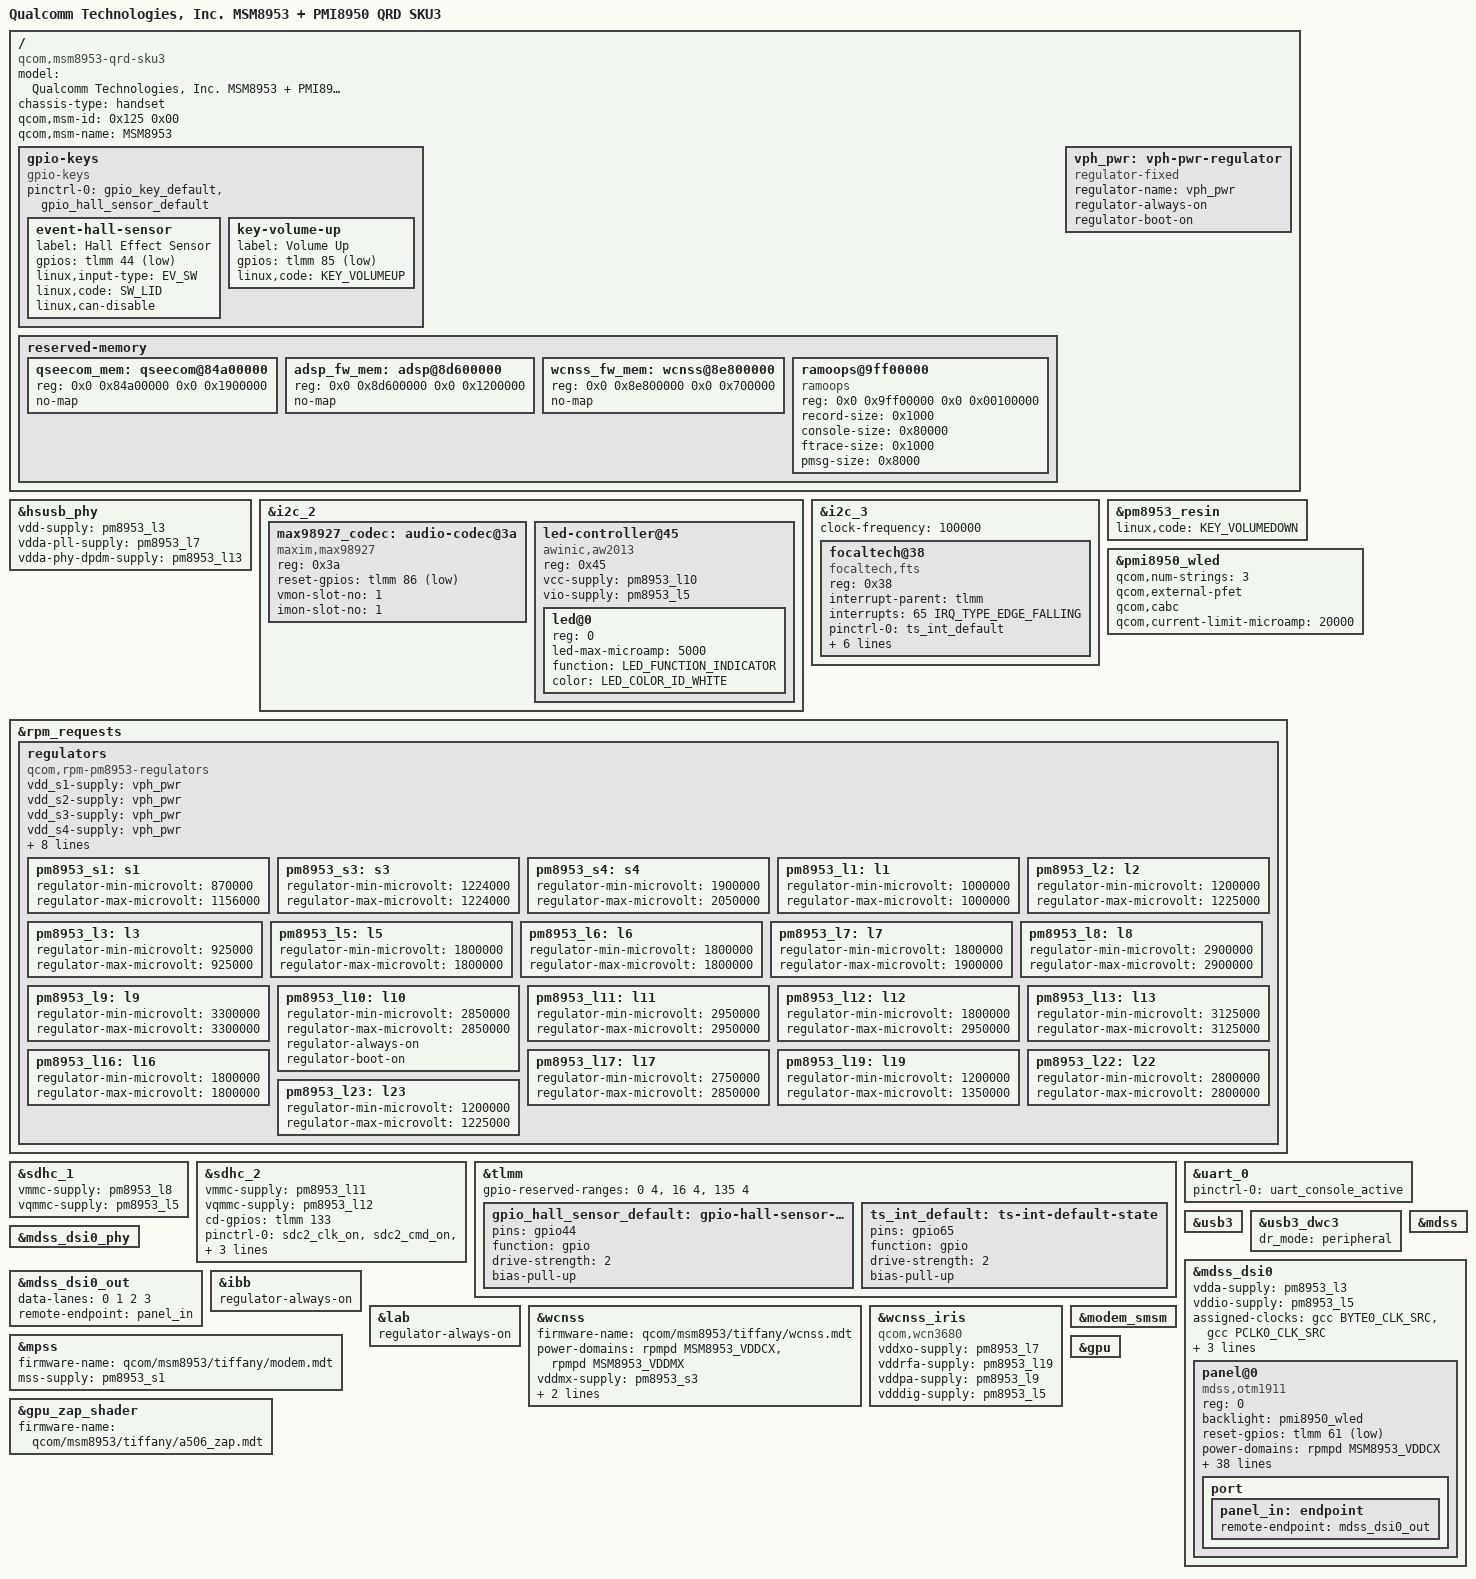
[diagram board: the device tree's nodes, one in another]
// SPDX-License-Identifier: BSD-3-Clause
/*
 * Copyright (c) 2022, Danila Tikhonov <JIaxyga@protonmail.com>
 * Copyright (c) 2022, Anton Bambura <jenneron@protonmail.com>
 */
/dts-v1/;

#include "msm8953.dtsi"
#include "pm8953.dtsi"
#include "pmi8950.dtsi"
#include <dt-bindings/leds/common.h>
#include <dt-bindings/gpio/gpio.h>
#include <dt-bindings/clock/qcom,gcc-msm8953.h>

/delete-node/ &adsp_fw_mem;
/delete-node/ &qseecom_mem;
/delete-node/ &wcnss_fw_mem;

/ {
	model = "Qualcomm Technologies, Inc. MSM8953 + PMI8950 QRD SKU3";
	compatible = "qcom,msm8953-qrd-sku3\0qcom,msm8953-qrd\0qcom,msm8953\0qcom,qrd";
	chassis-type = "handset";
	qcom,msm-id = <0x125 0x00>;
	qcom,msm-name = "MSM8953";
	gpio-keys {
		compatible = "gpio-keys";

		pinctrl-names = "default";
		pinctrl-0 = <&gpio_key_default>, <&gpio_hall_sensor_default>;

		event-hall-sensor {
			label = "Hall Effect Sensor";
			gpios = <&tlmm 44 GPIO_ACTIVE_LOW>;
			linux,input-type = <EV_SW>;
			linux,code = <SW_LID>;
			linux,can-disable;
		};

		key-volume-up {
			label = "Volume Up";
			gpios = <&tlmm 85 GPIO_ACTIVE_LOW>;
			linux,code = <KEY_VOLUMEUP>;
		};
	};

	reserved-memory {
		qseecom_mem: qseecom@84a00000 {
			reg = <0x0 0x84a00000 0x0 0x1900000>;
			no-map;
		};

		adsp_fw_mem: adsp@8d600000 {
			reg = <0x0 0x8d600000 0x0 0x1200000>;
			no-map;
		};

		wcnss_fw_mem: wcnss@8e800000 {
			reg = <0x0 0x8e800000 0x0 0x700000>;
			no-map;
		};

		ramoops@9ff00000 {
			compatible = "ramoops";
			reg = <0x0 0x9ff00000 0x0 0x00100000>;
			record-size = <0x1000>;
			console-size = <0x80000>;
			ftrace-size = <0x1000>;
			pmsg-size = <0x8000>;
		};
	};

	vph_pwr: vph-pwr-regulator {
		compatible = "regulator-fixed";
		regulator-name = "vph_pwr";
		regulator-always-on;
		regulator-boot-on;
	};
};

&hsusb_phy {
	vdd-supply = <&pm8953_l3>;
	vdda-pll-supply = <&pm8953_l7>;
	vdda-phy-dpdm-supply = <&pm8953_l13>;

	status = "okay";
};

&i2c_2 {
	status = "okay";

	max98927_codec: audio-codec@3a {
		compatible = "maxim,max98927";
		reg = <0x3a>;

		reset-gpios = <&tlmm 86 GPIO_ACTIVE_LOW>;

		vmon-slot-no = <1>;
		imon-slot-no = <1>;

		#sound-dai-cells = <0>;
	};

	led-controller@45 {
		compatible = "awinic,aw2013";
		reg = <0x45>;

		vcc-supply = <&pm8953_l10>;
		vio-supply = <&pm8953_l5>;

		#address-cells = <1>;
		#size-cells = <0>;

		led@0 {
			reg = <0>;
			led-max-microamp = <5000>;
			function = LED_FUNCTION_INDICATOR;
			color = <LED_COLOR_ID_WHITE>;
		};
	};
};

&i2c_3 {
	status = "okay";

	touchscreen@38 {
		compatible = "edt,edt-ft5406";
		reg = <0x38>;

		interrupt-parent = <&tlmm>;
		interrupts = <65 IRQ_TYPE_EDGE_FALLING>;

		pinctrl-names = "default";
		pinctrl-0 = <&ts_int_default>;

		reset-gpios = <&tlmm 64 GPIO_ACTIVE_LOW>;

		vcc-supply = <&pm8953_l10>;

		touchscreen-size-x = <1080>;
		touchscreen-size-y = <1920>;
	};
};

&pm8953_resin {
	linux,code = <KEY_VOLUMEDOWN>;
	status = "okay";
};

&pmi8950_wled {
	qcom,num-strings = <2>;
	qcom,external-pfet;
	qcom,cabc;

	status = "okay";
};

&rpm_requests {
	regulators {
		compatible = "qcom,rpm-pm8953-regulators";

		vdd_s1-supply = <&vph_pwr>;
		vdd_s2-supply = <&vph_pwr>;
		vdd_s3-supply = <&vph_pwr>;
		vdd_s4-supply = <&vph_pwr>;
		vdd_s5-supply = <&vph_pwr>;
		vdd_s6-supply = <&vph_pwr>;
		vdd_s7-supply = <&vph_pwr>;
		vdd_l1-supply = <&pm8953_s3>;
		vdd_l2_l3-supply = <&pm8953_s3>;
		vdd_l4_l5_l6_l7_l16_l19-supply = <&pm8953_s4>;
		vdd_l8_l11_l12_l13_l14_l15-supply = <&vph_pwr>;
		vdd_l9_l10_l17_l18_l22-supply = <&vph_pwr>;

		pm8953_s1: s1 {
			regulator-min-microvolt = <870000>;
			regulator-max-microvolt = <1156000>;
		};

		pm8953_s3: s3 {
			regulator-min-microvolt = <1224000>;
			regulator-max-microvolt = <1224000>;
		};

		pm8953_s4: s4 {
			regulator-min-microvolt = <1900000>;
			regulator-max-microvolt = <2050000>;
		};

		pm8953_l1: l1 {
			regulator-min-microvolt = <1000000>;
			regulator-max-microvolt = <1000000>;
		};

		pm8953_l2: l2 {
			regulator-min-microvolt = <1200000>;
			regulator-max-microvolt = <1225000>;
		};

		pm8953_l3: l3 {
			regulator-min-microvolt = <925000>;
			regulator-max-microvolt = <925000>;
		};

		pm8953_l5: l5 {
			regulator-min-microvolt = <1800000>;
			regulator-max-microvolt = <1800000>;
		};

		pm8953_l6: l6 {
			regulator-min-microvolt = <1800000>;
			regulator-max-microvolt = <1800000>;
		};

		pm8953_l7: l7 {
			regulator-min-microvolt = <1800000>;
			regulator-max-microvolt = <1900000>;
		};

		pm8953_l8: l8 {
			regulator-min-microvolt = <2900000>;
			regulator-max-microvolt = <2900000>;
		};

		pm8953_l9: l9 {
			regulator-min-microvolt = <3300000>;
			regulator-max-microvolt = <3300000>;
		};

		pm8953_l10:l10 {
			regulator-min-microvolt = <2850000>;
			regulator-max-microvolt = <2850000>;
		};

		pm8953_l11: l11 {
			regulator-min-microvolt = <2950000>;
			regulator-max-microvolt = <2950000>;
		};

		pm8953_l12: l12 {
			regulator-min-microvolt = <1800000>;
			regulator-max-microvolt = <2950000>;
		};

		pm8953_l13: l13 {
			regulator-min-microvolt = <3125000>;
			regulator-max-microvolt = <3125000>;
		};

		pm8953_l16: l16 {
			regulator-min-microvolt = <1800000>;
			regulator-max-microvolt = <1800000>;
		};

		pm8953_l17: l17 {
			regulator-min-microvolt = <2750000>;
			regulator-max-microvolt = <2850000>;
		};

		pm8953_l19: l19 {
			regulator-min-microvolt = <1200000>;
			regulator-max-microvolt = <1350000>;
		};

		pm8953_l22: l22 {
			regulator-min-microvolt = <2800000>;
			regulator-max-microvolt = <2800000>;
		};

		pm8953_l23: l23 {
			regulator-min-microvolt = <1200000>;
			regulator-max-microvolt = <1225000>;
		};
	};
};

&sdhc_1 {
	vmmc-supply = <&pm8953_l8>;
	vqmmc-supply = <&pm8953_l5>;

	status = "okay";
};

&sdhc_2 {
	vmmc-supply = <&pm8953_l11>;
	vqmmc-supply = <&pm8953_l12>;

	cd-gpios = <&tlmm 133 GPIO_ACTIVE_HIGH>;

	pinctrl-names = "default", "sleep";
	pinctrl-0 = <&sdc2_clk_on &sdc2_cmd_on &sdc2_data_on &sdc2_cd_on>;
	pinctrl-1 = <&sdc2_clk_off &sdc2_cmd_off &sdc2_data_off &sdc2_cd_off>;

	status = "okay";
};

&tlmm {
	gpio-reserved-ranges = <0 4>, <16 4>, <135 4>;

	gpio_hall_sensor_default: gpio-hall-sensor-state {
		pins = "gpio44";
		function = "gpio";
		drive-strength = <2>;
		bias-pull-up;
	};

	ts_int_default: ts-int-default-state {
		pins = "gpio65";
		function = "gpio";
		drive-strength = <2>;
		bias-pull-up;
	};
};

&uart_0 {
	pinctrl-names = "default";
	pinctrl-0 = <&uart_console_active>;

	status = "okay";
};

&usb3 {
	status = "okay";
};

&usb3_dwc3 {
	/delete-property/ usb-role-switch;
	dr_mode = "peripheral";
};
&pmi8950_wled {
    status = "okay";
    qcom,current-limit-microamp = <20000>;
    qcom,num-strings = <3>;
//    qcom,ovp-millivolt = <29500>;
//    qcom,external-pfet;
//    qcom,cabc;
};
/* ----- 面板供电（由 DSI 控制器管理）----- */
/* 注：vdd/vddio 已在 DSI 控制器的 vdda-supply/vddio-supply 中配置，
 * lab/ibb 由 qcom,mdss_dsi_ctrl0 的 lab-supply/ibb-supply 管理，
 * 因此面板节点只需引用背光和复位 GPIO。
 */

/* ----- 背光（WLED）配置 ----- */
&pmi8950_wled {
    status = "okay";
    qcom,current-limit-microamp = <20000>;
    qcom,num-strings = <3>;
};

&mdss {
    status = "okay";
};

&mdss_dsi0_phy {
    status = "okay";
};

&mdss_dsi0 {
    status = "okay";

    /* 供电（添加） */
    vdda-supply = <&pm8953_l3>;
    vddio-supply = <&pm8953_l5>;

    /* 时钟分配 - 使用与 msm8953.dtsi 相同的写法 */
    assigned-clocks = <&gcc BYTE0_CLK_SRC>,
                      <&gcc PCLK0_CLK_SRC>;
    assigned-clock-parents = <&mdss_dsi0_phy DSI_BYTE_PLL_CLK>,
                             <&mdss_dsi0_phy DSI_PIXEL_PLL_CLK>;

    panel@0 {
        compatible = "mdss,otm1911";
        reg = <0>;
        status = "okay";

        backlight = <&pmi8950_wled>;
        reset-gpios = <&tlmm 61 GPIO_ACTIVE_LOW>;
	power-domains = <&rpmpd MSM8953_VDDCX>;
	power-domain-names = "cx";
        /* ---- 时序参数（从原厂 DTS 完整复制） ---- */
        qcom,mdss-dsi-panel-name = "otm1911 fhd video mode dsi panel";
        qcom,mdss-dsi-panel-type = "dsi_video_mode";
        qcom,mdss-dsi-panel-framerate = <0x3c>;
        qcom,mdss-dsi-virtual-channel-id = <0x00>;
        qcom,mdss-dsi-stream = <0x00>;
        qcom,mdss-dsi-panel-width = <0x438>;
        qcom,mdss-dsi-panel-height = <0x780>;
        qcom,mdss-dsi-h-front-porch = <0x18>;
        qcom,mdss-dsi-h-back-porch = <0x18>;
        qcom,mdss-dsi-h-pulse-width = <0x14>;
        qcom,mdss-dsi-h-sync-skew = <0x00>;
        qcom,mdss-dsi-v-back-porch = <0x06>;
        qcom,mdss-dsi-v-front-porch = <0x0e>;
        qcom,mdss-dsi-v-pulse-width = <0x02>;
        qcom,mdss-dsi-h-left-border = <0x00>;
        qcom,mdss-dsi-h-right-border = <0x00>;
        qcom,mdss-dsi-v-top-border = <0x00>;
        qcom,mdss-dsi-v-bottom-border = <0x00>;
        qcom,mdss-dsi-bpp = <0x18>;
        qcom,mdss-dsi-underflow-color = <0xff>;
        qcom,mdss-dsi-border-color = <0x00>;

        qcom,mdss-dsi-on-command = [39 01 00 00 00 00 02 51 ff 39 01 00 00 00 00 02 53 2c 39 01 00 00 00 00 02 55 00 39 01 00 00 78 00 02 11 00 39 01 00 00 14 00 02 29 00];
        qcom,mdss-dsi-off-command = [39 01 00 00 32 00 02 28 00 39 01 00 00 78 00 02 10 00];

	qcom,mdss-dsi-panel-timings-phy-v2 = <0x2320090a 0x60304a0 0x2320090a 0x60304a0 0x2320090a 0x60304a0 0x2320090a 0x60304a0 0x2326090a 0x60304a0>;
	qcom,mdss-dsi-t-clk-post = <0x0e>;
	qcom,mdss-dsi-t-clk-pre = <0x36>;

        qcom,mdss-dsi-bl-min-level = <0x01>;
        qcom,mdss-dsi-bl-max-level = <0xfff>;
        qcom,mdss-dsi-dma-trigger = "trigger_sw";
        qcom,mdss-dsi-mdp-trigger = "none";
        qcom,mdss-dsi-bl-pmic-control-type = "bl_ctrl_wled";
        qcom,mdss-dsi-reset-sequence = <0x01 0x14 0x00 0x14 0x01 0x14>;
        port {
            panel_in: endpoint {
                remote-endpoint = <&mdss_dsi0_out>;
            };
        };
    };
};

&mdss_dsi0_out {
    data-lanes = <0 1 2 3>;
    remote-endpoint = <&panel_in>;
};
&ibb {
    regulator-always-on;
};

&lab {
    regulator-always-on;
};
/* 确保触摸屏的 VCC 电源始终开启 */
&pm8953_l10 {
    regulator-always-on;
    regulator-boot-on;
};

/* 确保 I2C 总线启用 */
&i2c_3 {
	status = "okay";
	clock-frequency = <100000>;

	/delete-property/ dmas;
	/delete-property/ dma-names;

	/delete-node/ touchscreen@38;    /* ← 关键：干掉遗留的 edt 节点 */

	focaltech@38 {
		compatible = "focaltech,fts";
		reg = <0x38>;

		interrupt-parent = <&tlmm>;
		interrupts = <65 IRQ_TYPE_EDGE_FALLING>;

		pinctrl-names = "default";
		pinctrl-0 = <&ts_int_default>;

		focaltech,reset-gpio = <&tlmm 64 GPIO_ACTIVE_LOW>;
		focaltech,irq-gpio = <&tlmm 65 IRQ_TYPE_EDGE_FALLING>;
		focaltech,max-touch-number = <5>;
		focaltech,display-coords = <0 0 1080 1920>;

		vcc-supply = <&pm8953_l10>;
		iovcc-supply = <&pm8953_l5>;
	};
};

/* ==================== WCNSS (Wi-Fi + BT) ==================== */

&wcnss {
    status = "okay";
    firmware-name = "qcom/msm8953/tiffany/wcnss.mdt";

    /* ===== 关键 1：电源域 ===== */
    power-domains = <&rpmpd MSM8953_VDDCX>,
                    <&rpmpd MSM8953_VDDMX>;
    power-domain-names = "cx", "mx";

    /* ===== 关键 2：regulator 供电 ===== */
    vddmx-supply = <&pm8953_s3>;    /* MX 数字电源 1.225V */
    vddcx-supply = <&pm8953_s4>;    /* CX 数字电源 1.9V */
    vddpx-supply = <&pm8953_l5>;    /* 1.8V IO 电源 */
};

&wcnss_iris {
    compatible = "qcom,wcn3680";

    vddxo-supply  = <&pm8953_l7>;
    vddrfa-supply = <&pm8953_l19>;
    vddpa-supply  = <&pm8953_l9>;
    vdddig-supply = <&pm8953_l5>;
};



/* ==================== Modem (MSS) ==================== */

&mpss {
    status = "okay";
    firmware-name = "qcom/msm8953/tiffany/modem.mdt";

    /* 根据最新的补丁，MSM8953 的 MSS 使用 mss-supply 作为 regulator */
    mss-supply = <&pm8953_s1>;   /* 电压由 pm8953_s1 提供 */
};

&modem_smsm {
    status = "okay";
};


/* ==================== Adreno 506 GPU ==================== */

&gpu {
    status = "okay";
};

&gpu_zap_shader {
    status = "okay";
    firmware-name = "qcom/msm8953/tiffany/a506_zap.mdt";
};

